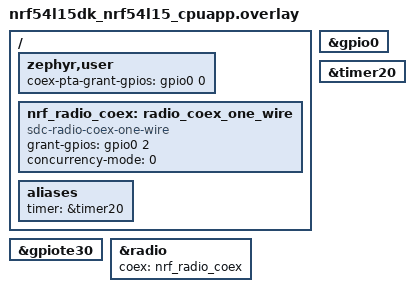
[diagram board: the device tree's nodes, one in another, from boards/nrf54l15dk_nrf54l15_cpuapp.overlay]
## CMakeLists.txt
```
# Copyright (c) 2021 Nordic Semiconductor ASA
#
# SPDX-License-Identifier: LicenseRef-Nordic-5-Clause
#

cmake_minimum_required(VERSION 3.20.0)

find_package(Zephyr REQUIRED HINTS $ENV{ZEPHYR_BASE})

project("External radio Bluetooth coexistence sample")

#if (NOT CONFIG_SOC_SERIES_NRF52X)
#  message(FATAL_ERROR "This sample is only supported on the nRF52 series.")
#endif()

# NORDIC SDK APP START
target_sources(app PRIVATE
  src/main.c
)
zephyr_include_directories(${ZEPHYR_BASE})
# NORDIC SDK APP END
```

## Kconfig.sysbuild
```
#
# Copyright (c) 2024 Nordic Semiconductor
#
# SPDX-License-Identifier: LicenseRef-Nordic-5-Clause
#

config NRF_DEFAULT_EMPTY
	default y if !SOC_NRF54H20_CPURAD

source "share/sysbuild/Kconfig"
```

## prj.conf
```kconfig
#
# Copyright (c) 2019 Nordic Semiconductor
#
# SPDX-License-Identifier: LicenseRef-Nordic-5-Clause
#

CONFIG_NCS_SAMPLES_DEFAULTS=y
CONFIG_ASSERT=y

CONFIG_BT=y
CONFIG_BT_PERIPHERAL=y
CONFIG_BT_DEVICE_NAME="Nordic_Bluetooth_1W_Coex"

CONFIG_CONSOLE_SUBSYS=y
CONFIG_CONSOLE_GETCHAR=y
CONFIG_MPSL_CX=y
CONFIG_MPSL_CX_1WIRE=y

CONFIG_LOG_PRINTK=y
CONFIG_LOG_MODE_DEFERRED=y

CONFIG_NRF_REGTOOL_VERBOSITY=3

CONFIG_CLOCK_CONTROL_NRF2=y
```

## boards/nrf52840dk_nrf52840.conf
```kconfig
#
# Copyright (c) 2024 Nordic Semiconductor
#
# SPDX-License-Identifier: LicenseRef-Nordic-5-Clause
#

CONFIG_NRFX_TIMER1=y
```

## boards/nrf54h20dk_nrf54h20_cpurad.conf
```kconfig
#
# Copyright (c) 2024 Nordic Semiconductor
#
# SPDX-License-Identifier: LicenseRef-Nordic-5-Clause
#

#CONFIG_NRFX_TIMER022=y
```

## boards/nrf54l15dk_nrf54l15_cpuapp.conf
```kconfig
#
# Copyright (c) 2024 Nordic Semiconductor
#
# SPDX-License-Identifier: LicenseRef-Nordic-5-Clause
#

#CONFIG_NRFX_DPPI=y
```

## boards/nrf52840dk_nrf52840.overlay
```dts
/* Copyright (c) 2021 Nordic Semiconductor ASA
 *
 * SPDX-License-Identifier: LicenseRef-Nordic-5-Clause
 */

/ {
	zephyr,user {
		coex-pta-grant-gpios = <&gpio0 26 GPIO_ACTIVE_HIGH>;
	};

	nrf_radio_coex: radio_coex_one_wire {
		status = "okay";
		compatible = "sdc-radio-coex-one-wire";
		grant-gpios = <&gpio0 2 GPIO_ACTIVE_HIGH>;
		concurrency-mode = <0>;
	};

	aliases {
		timer = &timer1;
	};
};

&radio {
	coex = <&nrf_radio_coex>;
};
```

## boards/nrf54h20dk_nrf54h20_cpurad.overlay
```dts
/*
 * Copyright (c) 2024 Nordic Semiconductor ASA
 *
 * SPDX-License-Identifier: LicenseRef-Nordic-5-Clause
 */

/ {
/*
	chosen {
		zephyr,console = &uart136;
		zephyr,shell-uart = &uart136;
	};
*/
	aliases {
		timer = &timer022;
	};
};

&timer022 {
	status = "okay";
};

&dppic020 {
	status = "okay";
	source-channels = < 0 1 4 >;
	sink-channels = < 2 3 4 >;
};
/*
&uart136 {
	status = "okay";
	memory-regions = <&cpurad_dma_region>;
};

&cpuapp_dma_region {
	reg = <0xe80 0x80>;
};

&cpurad_dma_region {
	reg = <0xf00 DT_SIZE_K(4)>;
};
*/
```

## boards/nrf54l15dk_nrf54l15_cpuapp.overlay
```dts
/*
 * Copyright (c) 2024 Nordic Semiconductor ASA
 *
 * SPDX-License-Identifier: LicenseRef-Nordic-5-Clause
 */

/ {
	zephyr,user {
		coex-pta-grant-gpios = <&gpio0 0 GPIO_ACTIVE_HIGH>;
	};

	nrf_radio_coex: radio_coex_one_wire {
		status = "okay";
		compatible = "sdc-radio-coex-one-wire";
		grant-gpios = <&gpio0 2 GPIO_ACTIVE_HIGH>;
		concurrency-mode = <0>;
	};

	aliases {
		timer = &timer20;
	};
};

&gpio0 {
	status = "okay";
};

&gpiote30 {
	status = "okay";
};

&radio {
	coex = <&nrf_radio_coex>;
};

&timer20 {
	status = "okay";
};
/*
*&dppic10 {
*	status = "okay";
*};
*/
```

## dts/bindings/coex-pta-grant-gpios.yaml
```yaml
# Copyright (c) 2021 Nordic Semiconductor ASA
# SPDX-License-Identifier: LicenseRef-Nordic-5-Clause

description: |
    This is a representation of an external radio coexistence setup that has a
    one-pin control interface (GRANT).

include: base.yaml

properties:
  coex-pta-grant-gpios:
    type: phandle-array
    description: |
      A phandle to the GPIO controller that controls the GRANT signal.
      The GPIO controller must be defined in the device tree.
    required: true

compatible: "coex-pta-grant-gpios"
```

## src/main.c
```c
/*
 * Copyright (c) 2021 Nordic Semiconductor ASA
 *
 * SPDX-License-Identifier: LicenseRef-Nordic-5-Clause
 */

#include <stddef.h>
#include <zephyr/sys/printk.h>
#include <zephyr/sys/__assert.h>

#include <zephyr/bluetooth/bluetooth.h>
#include <zephyr/console/console.h>
#include <zephyr/drivers/gpio.h>

#include <hal/nrf_radio.h>
#include <hal/nrf_timer.h>
#include <helpers/nrfx_gppi.h>
#include <nrfx_gpiote.h>
#include <nrfx_timer.h>
#include <hal/nrf_gpio.h>
#include <hal/nrf_egu.h>
#include <nrfx_dppi.h>
#include <hal/nrf_ppib.h>

/* Predefined channels for radio events. */
#include <protocol/mpsl_dppi_protocol_api.h>

#include <zephyr/drivers/clock_control/nrf_clock_control.h>

#define APP_COUNTER ((NRF_TIMER_Type *) DT_REG_ADDR(DT_ALIAS(timer)))
#define APP_COUNTER_RADIO_ACTIVITY_CC 0

#define APP_GRANT_ACTIVE_LOW                                                                       \
	(GPIO_ACTIVE_LOW & DT_GPIO_FLAGS(COEX_NODE, grant_gpios) ? true : false)

#define DEVICE_NAME CONFIG_BT_DEVICE_NAME
#define DEVICE_NAME_LEN (sizeof(DEVICE_NAME) - 1)

static const struct bt_data ad[] = {
	BT_DATA_BYTES(BT_DATA_FLAGS, (BT_LE_AD_GENERAL | BT_LE_AD_NO_BREDR)),
	BT_DATA(BT_DATA_NAME_COMPLETE, DEVICE_NAME, DEVICE_NAME_LEN),
};

static const struct device *sample_clock_dev = DEVICE_DT_GET(DT_CLOCKS_CTLR(DT_NODELABEL(timer022)));
static struct onoff_client cli;

#define CONFIG_SAMPLE_CLOCK_FREQUENCY_HZ 16000000
#define CONFIG_SAMPLE_CLOCK_ACCURACY_PPM NRF_CLOCK_CONTROL_ACCURACY_MAX
#define CONFIG_SAMPLE_CLOCK_PRECISION 0

#define SAMPLE_NOTIFY_TIMEOUT       K_SECONDS(2)

static const struct nrf_clock_spec spec = {
	.frequency = CONFIG_SAMPLE_CLOCK_FREQUENCY_HZ,
	.accuracy = CONFIG_SAMPLE_CLOCK_ACCURACY_PPM,
	.precision = CONFIG_SAMPLE_CLOCK_PRECISION,
};

static K_SEM_DEFINE(sample_sem, 0, 1);

static void sample_notify_cb(void)
{
	k_sem_give(&sample_sem);
}

static void console_print_thread(void)
{
	while (1) {
		nrf_timer_task_trigger(APP_COUNTER,
				       nrf_timer_capture_task_get(APP_COUNTER_RADIO_ACTIVITY_CC));

		printk("Number of radio events in the last second: %d\n",
		       nrf_timer_cc_get(APP_COUNTER, APP_COUNTER_RADIO_ACTIVITY_CC));

		nrf_timer_task_trigger(APP_COUNTER, NRF_TIMER_TASK_CLEAR);

		k_sleep(K_MSEC(1000));
	}
}

static int clock_setup(void)
{
	int ret;
	int res;
	int64_t req_start_uptime;
	int64_t req_stop_uptime;

	printk("\n");
	printk("minimum frequency request: %uHz\n", CONFIG_SAMPLE_CLOCK_FREQUENCY_HZ);
	printk("minimum accuracy request: %uPPM\n", CONFIG_SAMPLE_CLOCK_ACCURACY_PPM);
	printk("minimum precision request: %u\n", CONFIG_SAMPLE_CLOCK_PRECISION);

	sys_notify_init_callback(&cli.notify, sample_notify_cb);

	printk("\n");
	printk("requesting minimum clock specs\n");
	req_start_uptime = k_uptime_get();
	ret = nrf_clock_control_request(sample_clock_dev, &spec, &cli);
	if (ret < 0) {
		printk("minimum clock specs could not be met\n");
		return 0;
	}

	ret = k_sem_take(&sample_sem, SAMPLE_NOTIFY_TIMEOUT);
	if (ret < 0) {
		printk("timed out waiting for clock to meet request\n");
		return 0;
	}

	req_stop_uptime = k_uptime_get();

	ret = sys_notify_fetch_result(&cli.notify, &res);
	if (ret < 0) {
		printk("sys notify fetch failed\n");
		return 0;
	}

	if (res < 0) {
		printk("failed to apply request to clock\n");
		return 0;
	}

	printk("request applied to clock in %llims\n", req_stop_uptime - req_start_uptime);

	return 0;
}

static void setup_radio_event_counter(void)
{
	/* This function sets up a timer as a counter to count radio events. */
	nrf_timer_mode_set(APP_COUNTER, NRF_TIMER_MODE_LOW_POWER_COUNTER);

	/* Radio events are published on predefined channels.
	 */
	uint8_t ready_channel = MPSL_DPPI_RADIO_PUBLISH_READY_CHANNEL_IDX;

	NRF_DPPI_ENDPOINT_SETUP(nrf_timer_task_address_get(APP_COUNTER, NRF_TIMER_TASK_COUNT),
				ready_channel);
}

int main(void)
{
	printk("Starting Radio Coex Demo 1wire on board %s\n", CONFIG_BOARD);

	clock_setup();

	if (bt_enable(NULL)) {
		printk("Bluetooth init failed");
		return 0;
	}

	printk("Bluetooth initialized\n");

	setup_radio_event_counter();

	if (bt_le_adv_start(BT_LE_ADV_NCONN, ad, ARRAY_SIZE(ad), NULL, 0)) {
		printk("Advertising failed to start");
		return 0;
	}

	printk("Advertising started\n");

	while (1) {
		k_sleep(K_FOREVER);
	}
}

K_THREAD_DEFINE(console_print_thread_id, CONFIG_MAIN_STACK_SIZE, console_print_thread, NULL, NULL,
		NULL, K_LOWEST_APPLICATION_THREAD_PRIO, 0, 0);
```
